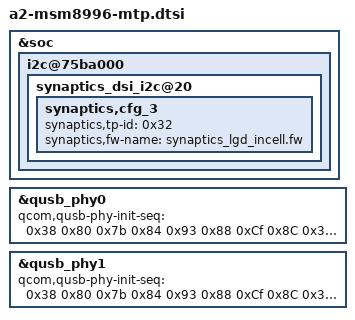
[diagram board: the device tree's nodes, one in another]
/* Copyright (c) 2015, The Linux Foundation. All rights reserved.
 * Copyright (C) 2018 XiaoMi, Inc.
 *
 * This program is free software; you can redistribute it and/or modify
 * it under the terms of the GNU General Public License version 2 and
 * only version 2 as published by the Free Software Foundation.
 *
 * This program is distributed in the hope that it will be useful,
 * but WITHOUT ANY WARRANTY; without even the implied warranty of
 * MERCHANTABILITY or FITNESS FOR A PARTICULAR PURPOSE.  See the
 * GNU General Public License for more details.
 */

#include "msm8996-xiaomi-gemini-common.dtsi"

&soc {
	i2c@75ba000 {
		synaptics_dsi_i2c@20 {
			synaptics,cfg_3 {
				synaptics,tp-id = /bits/ 8 <0x32>;
				synaptics,fw-name = "synaptics_lgd_incell.fw";
			};
		};
	};
};

&qusb_phy0 {
		qcom,qusb-phy-init-seq = <0x38 0x80
				0x7b 0x84
				0x93 0x88
				0xCf 0x8C
				0x30 0x08
				0x79 0x0C
				0x21 0x10
				0x14 0x9C
				0x9F 0x1C
				0x00 0x18>;
};

&qusb_phy1 {
		qcom,qusb-phy-init-seq = <0x38 0x80
				0x7b 0x84
				0x93 0x88
				0xCf 0x8C
				0x30 0x08
				0x79 0x0C
				0x21 0x10
				0x14 0x9C
				0x9F 0x1C
				0x00 0x18>;
};
